# GPIO0_GPIO0 register map
Vendor: Texas Instruments
Peripheral module from a debugger description file (folder AM263).
Registers are 32-bit, read-write, reset 0x0 unless marked. A register's access mark holds for its fields unless they carry their own. Offsets are as the file gives them; lines under a group give offsets from that group; [hi:lo] are bit positions; {n}, {i} and the like mark numbered series; 'fields as' and 'values as' point back to an identical list; <NAME> marks a mode.

## GPIO0_GPIO0
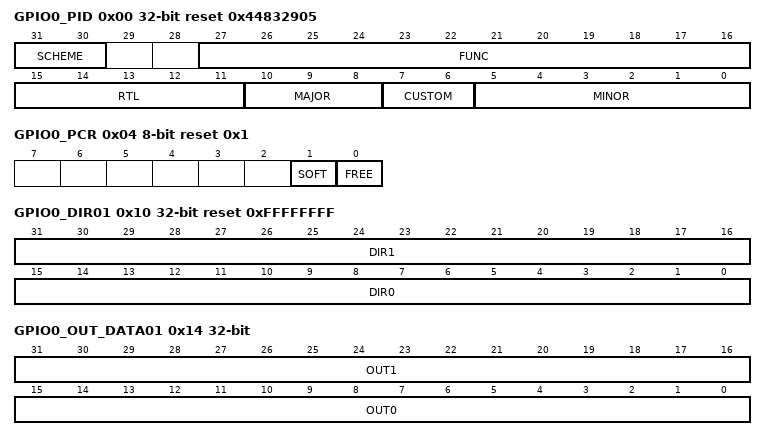
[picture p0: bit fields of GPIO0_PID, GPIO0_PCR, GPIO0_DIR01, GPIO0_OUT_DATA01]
0x00 GPIO0_PID ro reset 0x44832905
  [31:30] SCHEME — Current scheme
  [27:16] FUNC — Function code assigned to TCP3
  [15:11] RTL — RTL Version R code
  [10:8] MAJOR — Major revision X code
  [7:6] CUSTOM — Custom version code
  [5:0] MINOR — Minor revision Y code
0x04 GPIO0_PCR 8-bit ro reset 0x1
  [1] SOFT — Used in conjunction with FREE bit to determine the emulation suspend mode.
  [0] FREE — For GPIO, the FREE bit is fixed at 1, which means GPIO runs free in emulation suspend.
0x08 GPIO0_BINTEN
  [15:0] EN — Per bank interrupt enable. 0 = disable, 1 = enable.
0x10 GPIO0_DIR01 reset 0xFFFFFFFF
  [31:16] DIR1 — Direction of GPIO bank 1 bits, 0 = output, 1 = input.
  [15:0] DIR0 — Direction of GPIO bank 0 bits, 0 = output, 1 = input.
0x14 GPIO0_OUT_DATA01
  [31:16] OUT1 — Output drive state of GPIO bank 1 bits, does not affect operation when it is configured as input. Reading it returns the output drive state.
  [15:0] OUT0 — Output drive state of GPIO bank 0 bits, does not affect operation when it is configured as input. Reading it returns the output drive state.
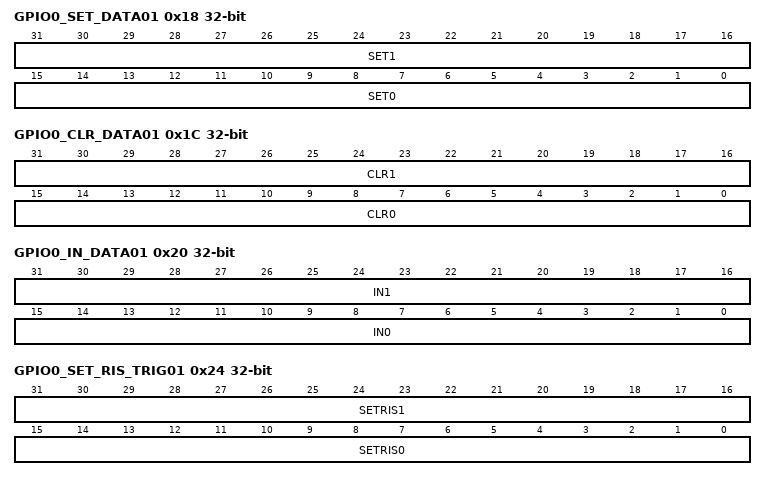
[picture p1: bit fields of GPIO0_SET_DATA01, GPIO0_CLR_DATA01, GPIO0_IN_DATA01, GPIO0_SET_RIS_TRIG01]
0x18 GPIO0_SET_DATA01
  [31:16] SET1 — Writing 1 sets the output drive state of GPIO bank 1 bits. Reading it returns the output drive state.
  [15:0] SET0 — Writing 1 sets the output drive state of GPIO bank 0 bits. Reading it returns the output drive state.
0x1C GPIO0_CLR_DATA01
  [31:16] CLR1 — Writing 1 clears the output drive state of GPIO. Reading it returns the output drive state.
  [15:0] CLR0 — Writing 1 clears the output drive state of GPIO. Reading it returns the output drive state.
0x20 GPIO0_IN_DATA01 ro
  [31:16] IN1 — Status of GPIO bank 1 bits.
  [15:0] IN0 — Status of GPIO bank 0 bits.
0x24 GPIO0_SET_RIS_TRIG01
  [31:16] SETRIS1 — Writing 1 enables rising edge detection for GPIO bank 1 bits.
  [15:0] SETRIS0 — Writing 1 enables rising edge detection for GPIO bank 0 bits.
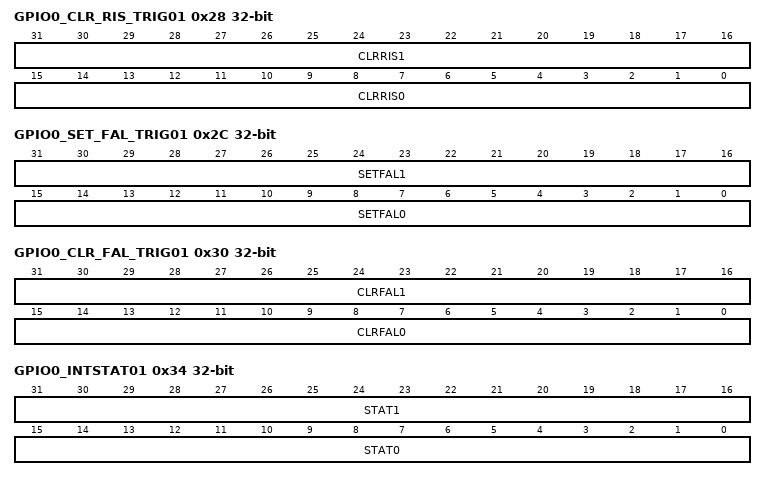
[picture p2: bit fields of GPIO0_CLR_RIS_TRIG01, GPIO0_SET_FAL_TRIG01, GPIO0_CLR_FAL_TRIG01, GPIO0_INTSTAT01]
0x28 GPIO0_CLR_RIS_TRIG01
  [31:16] CLRRIS1 — Writing 1 clears rising edge detection for GPIO bank 1 bits.
  [15:0] CLRRIS0 — Writing 1 clears rising edge detection for GPIO bank 0 bits.
0x2C GPIO0_SET_FAL_TRIG01
  [31:16] SETFAL1 — Writing 1 enables falling edge detection for for GPIO bank 1 bits.
  [15:0] SETFAL0 — Writing 1 enables falling edge detection for for GPIO bank 0 bits.
0x30 GPIO0_CLR_FAL_TRIG01
  [31:16] CLRFAL1 — Writing 1 clears falling edge detection for for GPIO bank 1 bits.
  [15:0] CLRFAL0 — Writing 1 clears falling edge detection for for GPIO bank 0 bits.
0x34 GPIO0_INTSTAT01
  [31:16] STAT1 — Status of GPIO bank 0 bits interrupt. Reading back 1 = interrupt occurred. 0 = interrupt hasnt occurred since last cleared. Writing 1 clears the corresponding interrupt status.
  [15:0] STAT0 — Status of GPIO bank 0 bits interrupt. Reading back 1 = interrupt occurred. 0 = interrupt hasnt occurred since last cleared. Writing 1 clears the corresponding interrupt status.
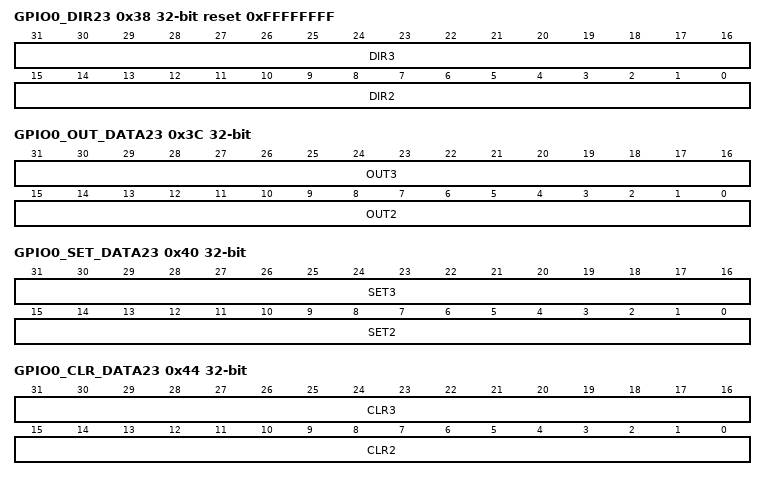
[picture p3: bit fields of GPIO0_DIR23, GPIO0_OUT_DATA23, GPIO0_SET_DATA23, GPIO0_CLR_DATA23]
0x38 GPIO0_DIR23 reset 0xFFFFFFFF
  [31:16] DIR3 — Direction of GPIO bank 3 bits, 0 = output, 1 = input.
  [15:0] DIR2 — Direction of GPIO bank 2 bits, 0 = output, 1 = input.
0x3C GPIO0_OUT_DATA23
  [31:16] OUT3 — Output drive state of GPIO bank 3 bits, does not affect operation when it is configured as input. Reading it returns the output drive state.
  [15:0] OUT2 — Output drive state of GPIO bank 2 bits, does not affect operation when it is configured as input. Reading it returns the output drive state.
0x40 GPIO0_SET_DATA23
  [31:16] SET3 — Writing 1 sets the output drive state of GPIO bank 3 bits. Reading it returns the output drive state.
  [15:0] SET2 — Writing 1 sets the output drive state of GPIO bank 2 bits. Reading it returns the output drive state.
0x44 GPIO0_CLR_DATA23
  [31:16] CLR3 — Writing 1 clears the output drive state of GPIO. Reading it returns the output drive state.
  [15:0] CLR2 — Writing 1 clears the output drive state of GPIO. Reading it returns the output drive state.
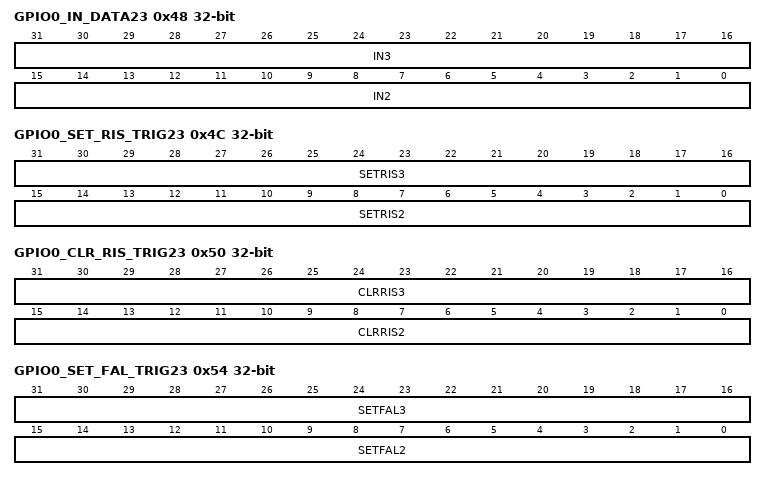
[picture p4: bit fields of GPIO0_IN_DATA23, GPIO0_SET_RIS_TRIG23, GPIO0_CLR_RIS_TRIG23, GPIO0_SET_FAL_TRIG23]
0x48 GPIO0_IN_DATA23 ro
  [31:16] IN3 — Status of GPIO bank 3 bits.
  [15:0] IN2 — Status of GPIO bank 2 bits.
0x4C GPIO0_SET_RIS_TRIG23
  [31:16] SETRIS3 — Writing 1 enables rising edge detection for GPIO bank 3 bits.
  [15:0] SETRIS2 — Writing 1 enables rising edge detection for GPIO bank 2 bits.
0x50 GPIO0_CLR_RIS_TRIG23
  [31:16] CLRRIS3 — Writing 1 clears rising edge detection for GPIO bank 3 bits.
  [15:0] CLRRIS2 — Writing 1 clears rising edge detection for GPIO bank 2 bits.
0x54 GPIO0_SET_FAL_TRIG23
  [31:16] SETFAL3 — Writing 1 enables falling edge detection for for GPIO bank 3 bits.
  [15:0] SETFAL2 — Writing 1 enables falling edge detection for for GPIO bank 2 bits.
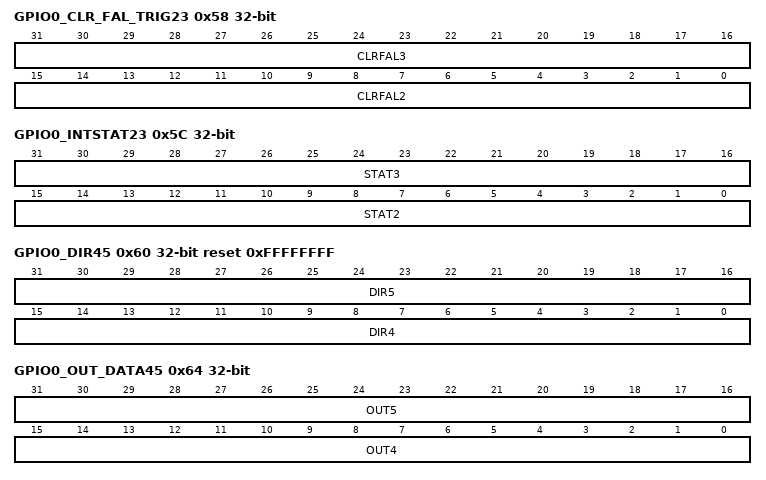
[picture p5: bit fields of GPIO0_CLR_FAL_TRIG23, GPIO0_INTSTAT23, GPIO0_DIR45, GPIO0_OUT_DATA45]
0x58 GPIO0_CLR_FAL_TRIG23
  [31:16] CLRFAL3 — Writing 1 clears falling edge detection for for GPIO bank 3 bits.
  [15:0] CLRFAL2 — Writing 1 clears falling edge detection for for GPIO bank 2 bits.
0x5C GPIO0_INTSTAT23
  [31:16] STAT3 — Status of GPIO bank 2 bits interrupt. Reading back 1 = interrupt occurred. 0 = interrupt hasnt occurred since last cleared. Writing 1 clears the corresponding interrupt status.
  [15:0] STAT2 — Status of GPIO bank 2 bits interrupt. Reading back 1 = interrupt occurred. 0 = interrupt hasnt occurred since last cleared. Writing 1 clears the corresponding interrupt status.
0x60 GPIO0_DIR45 reset 0xFFFFFFFF
  [31:16] DIR5 — Direction of GPIO bank 5 bits, 0 = output, 1 = input.
  [15:0] DIR4 — Direction of GPIO bank 4 bits, 0 = output, 1 = input.
0x64 GPIO0_OUT_DATA45
  [31:16] OUT5 — Output drive state of GPIO bank 5 bits, does not affect operation when it is configured as input. Reading it returns the output drive state.
  [15:0] OUT4 — Output drive state of GPIO bank 4 bits, does not affect operation when it is configured as input. Reading it returns the output drive state.
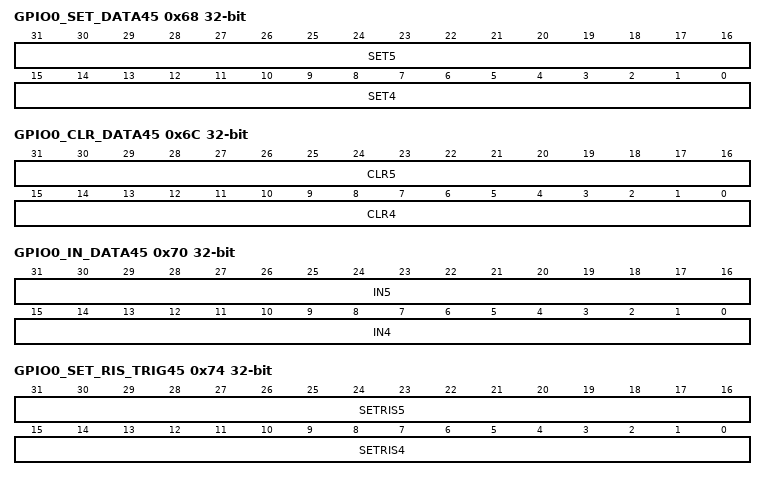
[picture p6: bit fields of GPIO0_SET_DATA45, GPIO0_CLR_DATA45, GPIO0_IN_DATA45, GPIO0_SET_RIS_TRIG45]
0x68 GPIO0_SET_DATA45
  [31:16] SET5 — Writing 1 sets the output drive state of GPIO bank 5 bits. Reading it returns the output drive state.
  [15:0] SET4 — Writing 1 sets the output drive state of GPIO bank 4 bits. Reading it returns the output drive state.
0x6C GPIO0_CLR_DATA45
  [31:16] CLR5 — Writing 1 clears the output drive state of GPIO. Reading it returns the output drive state.
  [15:0] CLR4 — Writing 1 clears the output drive state of GPIO. Reading it returns the output drive state.
0x70 GPIO0_IN_DATA45 ro
  [31:16] IN5 — Status of GPIO bank 5 bits.
  [15:0] IN4 — Status of GPIO bank 4 bits.
0x74 GPIO0_SET_RIS_TRIG45
  [31:16] SETRIS5 — Writing 1 enables rising edge detection for GPIO bank 5 bits.
  [15:0] SETRIS4 — Writing 1 enables rising edge detection for GPIO bank 4 bits.
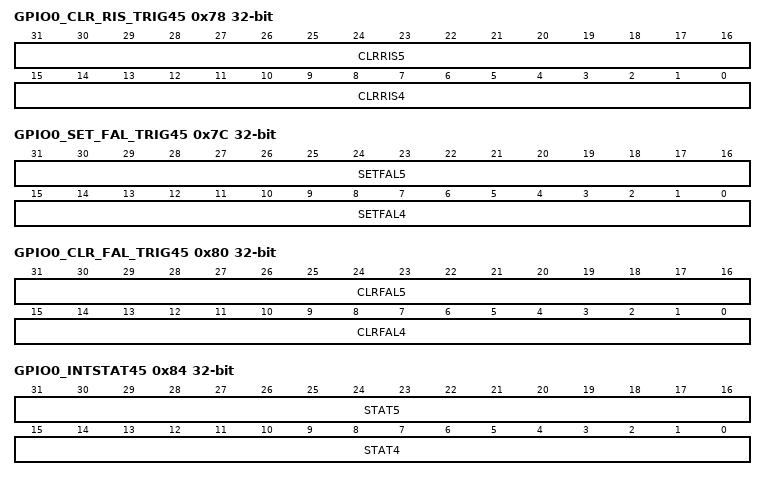
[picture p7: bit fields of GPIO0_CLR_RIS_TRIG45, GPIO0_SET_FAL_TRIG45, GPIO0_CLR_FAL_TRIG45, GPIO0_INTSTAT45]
0x78 GPIO0_CLR_RIS_TRIG45
  [31:16] CLRRIS5 — Writing 1 clears rising edge detection for GPIO bank 5 bits.
  [15:0] CLRRIS4 — Writing 1 clears rising edge detection for GPIO bank 4 bits.
0x7C GPIO0_SET_FAL_TRIG45
  [31:16] SETFAL5 — Writing 1 enables falling edge detection for for GPIO bank 5 bits.
  [15:0] SETFAL4 — Writing 1 enables falling edge detection for for GPIO bank 4 bits.
0x80 GPIO0_CLR_FAL_TRIG45
  [31:16] CLRFAL5 — Writing 1 clears falling edge detection for for GPIO bank 5 bits.
  [15:0] CLRFAL4 — Writing 1 clears falling edge detection for for GPIO bank 4 bits.
0x84 GPIO0_INTSTAT45
  [31:16] STAT5 — Status of GPIO bank 4 bits interrupt. Reading back 1 = interrupt occurred. 0 = interrupt hasnt occurred since last cleared. Writing 1 clears the corresponding interrupt status.
  [15:0] STAT4 — Status of GPIO bank 4 bits interrupt. Reading back 1 = interrupt occurred. 0 = interrupt hasnt occurred since last cleared. Writing 1 clears the corresponding interrupt status.
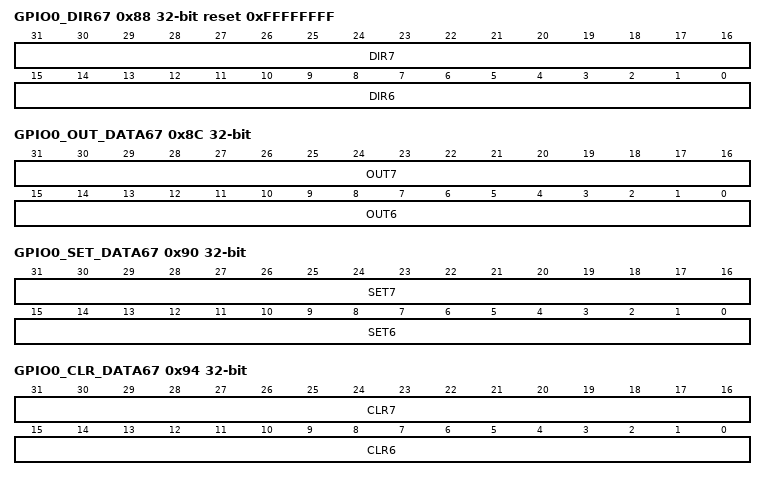
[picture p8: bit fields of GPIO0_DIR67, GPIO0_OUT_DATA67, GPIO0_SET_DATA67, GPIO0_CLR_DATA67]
0x88 GPIO0_DIR67 reset 0xFFFFFFFF
  [31:16] DIR7 — Direction of GPIO bank 7 bits, 0 = output, 1 = input.
  [15:0] DIR6 — Direction of GPIO bank 6 bits, 0 = output, 1 = input.
0x8C GPIO0_OUT_DATA67
  [31:16] OUT7 — Output drive state of GPIO bank 7 bits, does not affect operation when it is configured as input. Reading it returns the output drive state.
  [15:0] OUT6 — Output drive state of GPIO bank 6 bits, does not affect operation when it is configured as input. Reading it returns the output drive state.
0x90 GPIO0_SET_DATA67
  [31:16] SET7 — Writing 1 sets the output drive state of GPIO bank 7 bits. Reading it returns the output drive state.
  [15:0] SET6 — Writing 1 sets the output drive state of GPIO bank 6 bits. Reading it returns the output drive state.
0x94 GPIO0_CLR_DATA67
  [31:16] CLR7 — Writing 1 clears the output drive state of GPIO. Reading it returns the output drive state.
  [15:0] CLR6 — Writing 1 clears the output drive state of GPIO. Reading it returns the output drive state.
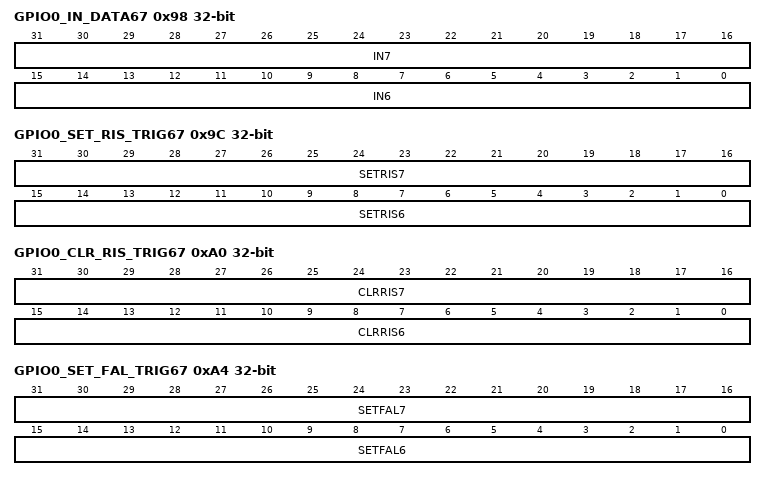
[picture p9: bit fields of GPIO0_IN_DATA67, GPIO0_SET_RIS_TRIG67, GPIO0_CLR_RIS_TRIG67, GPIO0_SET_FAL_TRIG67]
0x98 GPIO0_IN_DATA67 ro
  [31:16] IN7 — Status of GPIO bank 7 bits.
  [15:0] IN6 — Status of GPIO bank 6 bits.
0x9C GPIO0_SET_RIS_TRIG67
  [31:16] SETRIS7 — Writing 1 enables rising edge detection for GPIO bank 7 bits.
  [15:0] SETRIS6 — Writing 1 enables rising edge detection for GPIO bank 6 bits.
0xA0 GPIO0_CLR_RIS_TRIG67
  [31:16] CLRRIS7 — Writing 1 clears rising edge detection for GPIO bank 7 bits.
  [15:0] CLRRIS6 — Writing 1 clears rising edge detection for GPIO bank 6 bits.
0xA4 GPIO0_SET_FAL_TRIG67
  [31:16] SETFAL7 — Writing 1 enables falling edge detection for for GPIO bank 7 bits.
  [15:0] SETFAL6 — Writing 1 enables falling edge detection for for GPIO bank 6 bits.
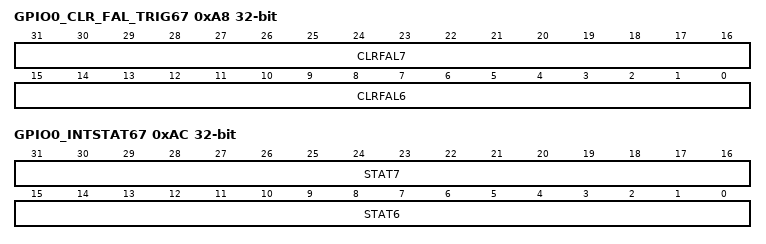
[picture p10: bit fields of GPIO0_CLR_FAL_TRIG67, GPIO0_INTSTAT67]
0xA8 GPIO0_CLR_FAL_TRIG67
  [31:16] CLRFAL7 — Writing 1 clears falling edge detection for for GPIO bank 7 bits.
  [15:0] CLRFAL6 — Writing 1 clears falling edge detection for for GPIO bank 6 bits.
0xAC GPIO0_INTSTAT67
  [31:16] STAT7 — Status of GPIO bank 6 bits interrupt. Reading back 1 = interrupt occurred. 0 = interrupt hasnt occurred since last cleared. Writing 1 clears the corresponding interrupt status.
  [15:0] STAT6 — Status of GPIO bank 6 bits interrupt. Reading back 1 = interrupt occurred. 0 = interrupt hasnt occurred since last cleared. Writing 1 clears the corresponding interrupt status.
0xB0 GPIO0_DIR8 reset 0xFFFF
  [15:0] DIR8 — Direction of GPIO bank 8 bits, 0 = output, 1 = input.
0xB4 GPIO0_OUT_DATA8
  [15:0] OUT8 — Output drive state of GPIO bank 8 bits, does not affect operation when it is configured as input. Reading it returns the output drive state.
0xB8 GPIO0_SET_DATA8
  [15:0] SET8 — Writing 1 sets the output drive state of GPIO bank 8 bits. Reading it returns the output drive state.
0xBC GPIO0_CLR_DATA8
  [15:0] CLR8 — Writing 1 clears the output drive state of GPIO. Reading it returns the output drive state.
0xC0 GPIO0_IN_DATA8 ro
  [15:0] IN8 — Status of GPIO bank 8 bits.
0xC4 GPIO0_SET_RIS_TRIG8 16-bit
  [15:0] SETRIS8 — Writing 1 enables rising edge detection for GPIO bank 8 bits.
0xC8 GPIO0_CLR_RIS_TRIG8 16-bit
  [15:0] CLRRIS8 — Writing 1 clears rising edge detection for GPIO bank 8 bits.
0xCC GPIO0_SET_FAL_TRIG8 16-bit
  [15:0] SETFAL8 — Writing 1 enables falling edge detection for for GPIO bank 8 bits.
0xD0 GPIO0_CLR_FAL_TRIG8 16-bit
  [15:0] CLRFAL8 — Writing 1 clears falling edge detection for for GPIO bank 8 bits.
0xD4 GPIO0_INTSTAT8
  [15:0] STAT8 — Status of GPIO bank 8 bits interrupt. Reading back 1 = interrupt occurred. 0 = interrupt hasnt occurred since last cleared. Writing 1 clears the corresponding interrupt status.
